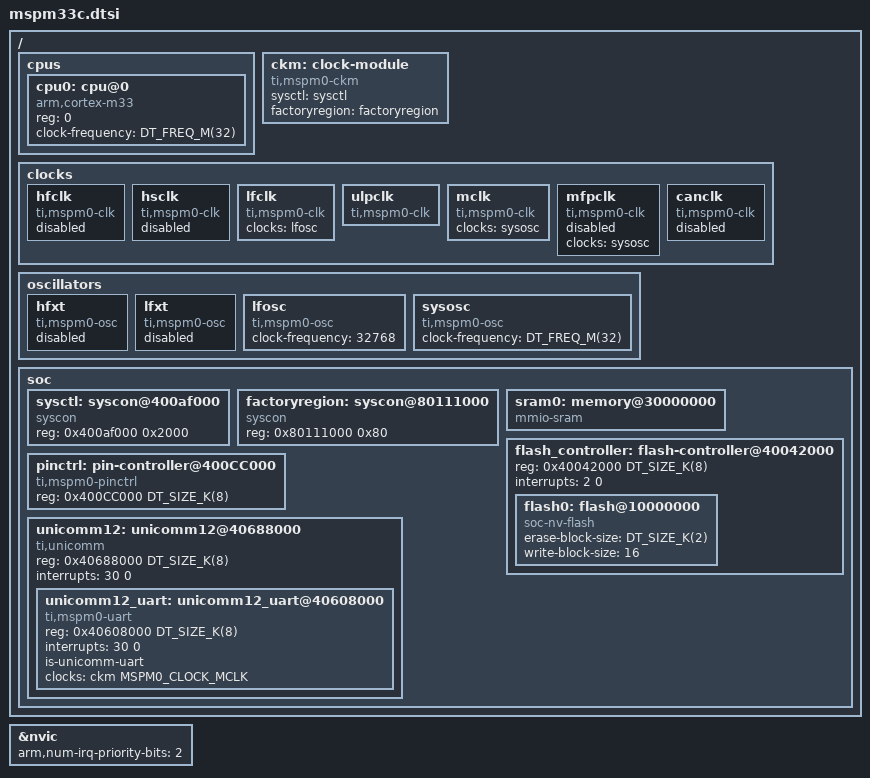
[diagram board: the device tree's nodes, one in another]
/*
 * Copyright (c) 2026 Texas Instruments
 * SPDX-License-Identifier: Apache-2.0
 */

#include <arm/armv8-m.dtsi>
#include <freq.h>
#include <zephyr/dt-bindings/clock/mspm0_clock.h>

/ {
	cpus {
		#address-cells = <1>;
		#size-cells = <0>;

		cpu0: cpu@0 {
			device_type = "cpu";
			compatible = "arm,cortex-m33";
			reg = <0>;
			clock-frequency = <DT_FREQ_M(32)>;
		};
	};

	ckm: clock-module {
		compatible = "ti,mspm0-ckm";
		#clock-cells = <1>;
		sysctl = <&sysctl>;
		factoryregion = <&factoryregion>;
	};

	clocks: clocks {
		hfclk: hfclk {
			#clock-cells = <0>;
			compatible = "ti,mspm0-clk";
			status = "disabled";
		};

		hsclk: hsclk {
			#clock-cells = <0>;
			compatible = "ti,mspm0-clk";
			status = "disabled";
		};

		lfclk: lfclk {
			#clock-cells = <0>;
			compatible = "ti,mspm0-clk";
			clocks = <&lfosc>;
		};

		ulpclk: ulpclk {
			#clock-cells = <0>;
			compatible = "ti,mspm0-clk";
		};

		mclk: mclk {
			#clock-cells = <0>;
			compatible = "ti,mspm0-clk";
			clocks = <&sysosc>;
		};

		mfpclk: mfpclk {
			#clock-cells = <0>;
			compatible = "ti,mspm0-clk";
			clocks = <&sysosc>;
			status = "disabled";
		};

		canclk: canclk {
			#clock-cells = <0>;
			compatible = "ti,mspm0-clk";
			status = "disabled";
		};
	};

	oscillators: oscillators {
		hfxt: hfxt {
			#clock-cells = <0>;
			compatible = "ti,mspm0-osc";
			status = "disabled";
		};

		lfxt: lfxt {
			#clock-cells = <0>;
			compatible = "ti,mspm0-osc";
			status = "disabled";
		};

		lfosc: lfosc {
			#clock-cells = <0>;
			compatible = "ti,mspm0-osc";
			clock-frequency = <32768>;
		};

		sysosc: sysosc {
			#clock-cells = <0>;
			compatible = "ti,mspm0-osc";
			clock-frequency = <DT_FREQ_M(32)>;
		};
	};

	soc {
		sysctl: syscon@400af000 {
			compatible = "syscon";
			reg = <0x400af000 0x2000>;
			status = "okay";
		};

		factoryregion: syscon@80111000 {
			compatible = "syscon";
			reg = <0x80111000 0x80>;
			status = "okay";
		};

		sram0: memory@30000000 {
			compatible = "mmio-sram";
		};

		flash_controller: flash-controller@40042000 {
			reg = <0x40042000 DT_SIZE_K(8)>;
			interrupts = <2 0>;
			ranges;
			#address-cells = <1>;
			#size-cells = <1>;

			flash0: flash@10000000 {
				compatible = "soc-nv-flash";
				erase-block-size = <DT_SIZE_K(2)>;
				write-block-size = <16>;
				#address-cells = <1>;
				#size-cells = <1>;
			};
		};

		pinctrl: pin-controller@400CC000 {
			compatible = "ti,mspm0-pinctrl";
			reg = <0x400CC000 DT_SIZE_K(8)>;
		};

		unicomm12: unicomm12@40688000 {
			reg = <0x40688000 DT_SIZE_K(8)>;
			compatible = "ti,unicomm";
			interrupts = <30 0>;
			#address-cells = <1>;
			#size-cells = <1>;

			unicomm12_uart: unicomm12_uart@40608000 {
				reg = <0x40608000 DT_SIZE_K(8)>;
				interrupts = <30 0>;
				#address-cells = <1>;
				#size-cells = <1>;
				compatible = "ti,mspm0-uart";
				is-unicomm-uart;
				clocks = <&ckm MSPM0_CLOCK_MCLK>;
			};
		};
	};
};

&nvic {
	arm,num-irq-priority-bits = <2>;
};
